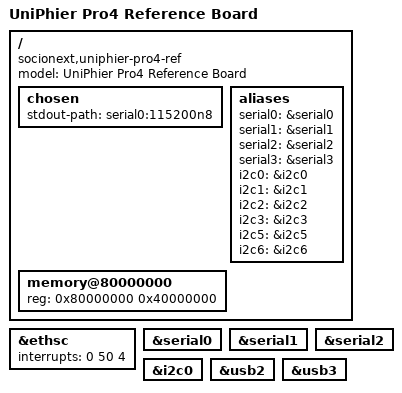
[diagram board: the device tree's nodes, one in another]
/*
 * Device Tree Source for UniPhier Pro4 Reference Board
 *
 * Copyright (C) 2015-2016 Socionext Inc.
 *   Author: Masahiro Yamada <yamada.masahiro@socionext.com>
 *
 * SPDX-License-Identifier: (GPL-2.0+ OR MIT)
 */

/dts-v1/;
/include/ "uniphier-pro4.dtsi"
/include/ "uniphier-ref-daughter.dtsi"
/include/ "uniphier-support-card.dtsi"

/ {
	model = "UniPhier Pro4 Reference Board";
	compatible = "socionext,uniphier-pro4-ref", "socionext,uniphier-pro4";

	chosen {
		stdout-path = "serial0:115200n8";
	};

	aliases {
		serial0 = &serial0;
		serial1 = &serial1;
		serial2 = &serial2;
		serial3 = &serial3;
		i2c0 = &i2c0;
		i2c1 = &i2c1;
		i2c2 = &i2c2;
		i2c3 = &i2c3;
		i2c5 = &i2c5;
		i2c6 = &i2c6;
	};

	memory@80000000 {
		device_type = "memory";
		reg = <0x80000000 0x40000000>;
	};
};

&ethsc {
	interrupts = <0 50 4>;
};

&serial0 {
	status = "okay";
};

&serial1 {
	status = "okay";
};

&serial2 {
	status = "okay";
};

&i2c0 {
	status = "okay";
};

&usb2 {
	status = "okay";
};

&usb3 {
	status = "okay";
};
